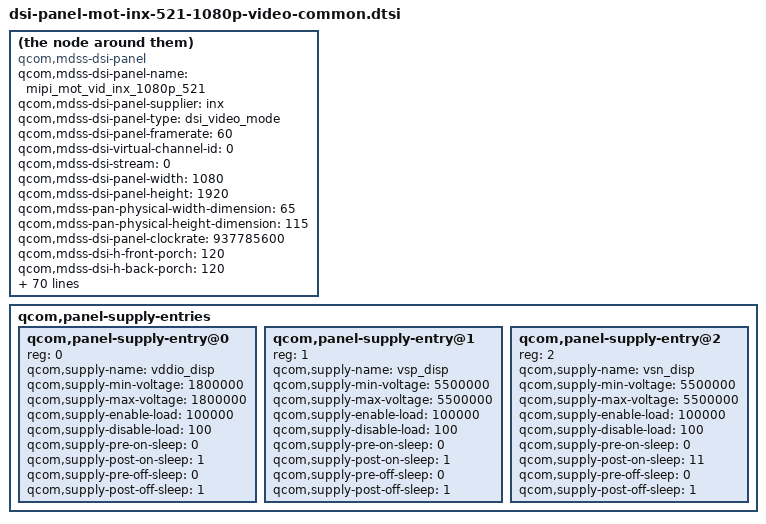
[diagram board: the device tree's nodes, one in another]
/* Copyright (c) 2016, The Linux Foundation. All rights reserved.
 *
 * This program is free software; you can redistribute it and/or modify
 * it under the terms of the GNU General Public License version 2 and
 * only version 2 as published by the Free Software Foundation.
 *
 * This program is distributed in the hope that it will be useful,
 * but WITHOUT ANY WARRANTY; without even the implied warranty of
 * MERCHANTABILITY or FITNESS FOR A PARTICULAR PURPOSE.  See the
 * GNU General Public License for more details.
 */

compatible = "qcom,mdss-dsi-panel";
qcom,mdss-dsi-panel-name = "mipi_mot_vid_inx_1080p_521";
qcom,mdss-dsi-panel-supplier = "inx";
qcom,mdss-dsi-panel-type = "dsi_video_mode";
qcom,mdss-dsi-panel-framerate = <60>;
qcom,mdss-dsi-virtual-channel-id = <0>;
qcom,mdss-dsi-stream = <0>;
qcom,mdss-dsi-panel-width = <1080>;
qcom,mdss-dsi-panel-height = <1920>;
qcom,mdss-pan-physical-width-dimension = <65>;
qcom,mdss-pan-physical-height-dimension = <115>;

qcom,mdss-dsi-panel-clockrate = <937785600>;
qcom,mdss-dsi-h-front-porch = <120>;
qcom,mdss-dsi-h-back-porch = <120>;
qcom,mdss-dsi-h-pulse-width = <20>;
qcom,mdss-dsi-h-sync-skew = <0>;
qcom,mdss-dsi-v-back-porch = <8>;
qcom,mdss-dsi-v-front-porch = <14>;
qcom,mdss-dsi-v-pulse-width = <2>;
qcom,mdss-dsi-h-left-border = <0>;
qcom,mdss-dsi-h-right-border = <0>;
qcom,mdss-dsi-v-top-border = <0>;
qcom,mdss-dsi-v-bottom-border = <0>;
qcom,mdss-dsi-bpp = <24>;
qcom,mdss-dsi-underflow-color = <0xff>;
qcom,mdss-dsi-border-color = <0>;
qcom,mdss-dsi-on-command = [
	15 00 00 00 00 00 02 FF EE
	15 01 00 00 0A 00 02 18 40
	15 01 00 00 0A 00 02 18 00
	15 00 00 00 00 00 02 FF 00
	15 00 00 00 00 00 02 FB 01
	15 00 00 00 00 00 02 D3 0A
	15 00 00 00 00 00 02 D4 0E
	05 01 00 00 78 00 01 11
	15 00 00 00 00 00 02 51 CC
	15 00 00 00 00 00 02 53 2C
	15 00 00 00 00 00 02 55 01
	05 01 00 00 00 00 01 29];		/* Display on */

qcom,mdss-dsi-off-command = [
	05 00 00 00 00 00 01 28		/* display_off */
	05 01 00 00 78 00 01 10];	/* enter sleep mode */

qcom,mdss-dsi-cabc-ui-command = [15 01 00 00 00 00 02 55 01];
qcom,mdss-dsi-cabc-ui-command-state = "dsi_hs_mode";
qcom,mdss-dsi-cabc-mv-command = [15 01 00 00 00 00 02 55 03];
qcom,mdss-dsi-cabc-mv-command-state = "dsi_hs_mode";
qcom,mdss-dsi-cabc-dis-command = [15 01 00 00 00 00 02 55 00];
qcom,mdss-dsi-cabc-dis-command-state = "dsi_hs_mode";
qcom,mdss-dsi-hbm-on-command = [15 01 00 00 00 00 02 51 FF];
qcom,mdss-dsi-hbm-on-command-state = "dsi_hs_mode";
qcom,mdss-dsi-hbm-off-command = [15 01 00 00 00 00 02 51 CC];
qcom,mdss-dsi-hbm-off-command-state = "dsi_hs_mode";
qcom,mdss-dsi-hbm-type = "lcd-dcs-wled";

qcom,mdss-dsi-on-command-state = "dsi_lp_mode";
qcom,mdss-dsi-off-command-state = "dsi_lp_mode";

qcom,mdss-dsi-h-sync-pulse = <0>;
qcom,mdss-dsi-traffic-mode = "burst_mode";
qcom,mdss-dsi-bllp-eof-power-mode;
qcom,mdss-dsi-bllp-power-mode;
qcom,mdss-dsi-lane-0-state;
qcom,mdss-dsi-lane-1-state;
qcom,mdss-dsi-lane-2-state;
qcom,mdss-dsi-lane-3-state;
qcom,mdss-dsi-panel-timings = [f2 3a 28 00 6c 70 2c 3e 2e 03 04 00];
qcom,mdss-dsi-t-clk-post = <0x2>;
qcom,mdss-dsi-t-clk-pre = <0x2d>;
qcom,mdss-dsi-bl-min-level = <1>;
qcom,mdss-dsi-bl-max-level = <4095>;
qcom,mdss-dsi-dma-trigger = "trigger_sw";
qcom,mdss-dsi-mdp-trigger = "none";
qcom,mdss-dsi-bl-pmic-control-type = "bl_ctrl_wled";
qcom,mdss-dsi-reset-sequence = <1 2>, <0 2>, <1 2>, <0 2>, <1 20>;
qcom,mdss-dsi-lp11-init;
qcom,mdss-dsi-tx-eot-append;

qcom,esd-check-enabled;
qcom,mdss-dsi-panel-status-check-mode = "reg_read";
qcom,mdss-dsi-panel-status-read-length = <1>;
qcom,mdss-dsi-panel-status-command = [06 01 00 01 00 00 01 0A];
qcom,mdss-dsi-panel-status-command-state = "dsi_hs_mode";
qcom,mdss-dsi-panel-status-value = <0x9c>;

qcom,panel-supply-entries {
	#address-cells = <1>;
	#size-cells = <0>;

	qcom,panel-supply-entry@0 {
		reg = <0>;
		qcom,supply-name = "vddio_disp";
		qcom,supply-min-voltage = <1800000>;
		qcom,supply-max-voltage = <1800000>;
		qcom,supply-enable-load = <100000>;
		qcom,supply-disable-load = <100>;
		qcom,supply-pre-on-sleep = <0>;
		qcom,supply-post-on-sleep = <1>;
		qcom,supply-pre-off-sleep = <0>;
		qcom,supply-post-off-sleep = <1>;
	};

	qcom,panel-supply-entry@1 {
		reg = <1>;
		qcom,supply-name = "vsp_disp";
		qcom,supply-min-voltage = <5500000>;
		qcom,supply-max-voltage = <5500000>;
		qcom,supply-enable-load = <100000>;
		qcom,supply-disable-load = <100>;
		qcom,supply-pre-on-sleep = <0>;
		qcom,supply-post-on-sleep = <1>;
		qcom,supply-pre-off-sleep = <0>;
		qcom,supply-post-off-sleep = <1>;
	};

	qcom,panel-supply-entry@2 {
		reg = <2>;
		qcom,supply-name = "vsn_disp";
		qcom,supply-min-voltage = <5500000>;
		qcom,supply-max-voltage = <5500000>;
		qcom,supply-enable-load = <100000>;
		qcom,supply-disable-load = <100>;
		qcom,supply-pre-on-sleep = <0>;
		qcom,supply-post-on-sleep = <11>;
		qcom,supply-pre-off-sleep = <0>;
		qcom,supply-post-off-sleep = <1>;
	};
};
